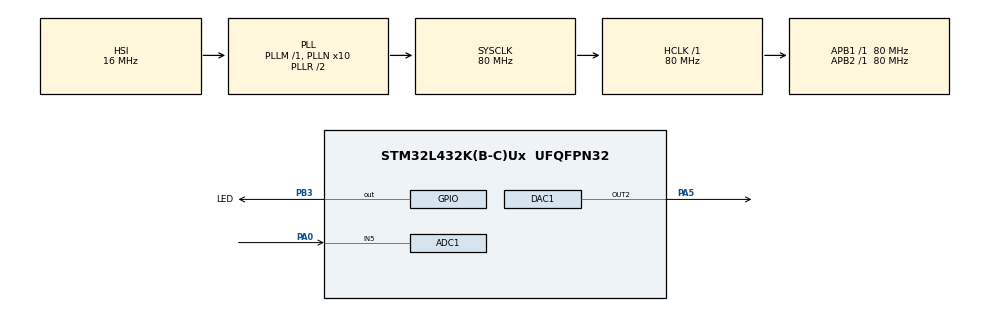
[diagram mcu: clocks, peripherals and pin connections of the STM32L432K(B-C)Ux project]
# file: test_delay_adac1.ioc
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Mcu.Family=STM32L4
RCC.MSI_VALUE=48000000
RCC.PLLSourceVirtual=RCC_PLLSOURCE_HSI
Dma.ADC1.0.Instance=DMA1_Channel1
RCC.CortexFreq_Value=80000000
DAC1.DAC_Channel-DAC_OUT2=DAC_CHANNEL_2
ADC1.Rank-0\#ChannelRegularConversion=1
SH.COMP_DAC12_group.0=DAC1_OUT2,DAC_OUT2
ADC1.OffsetNumber-0\#ChannelRegularConversion=ADC_OFFSET_NONE
PB3\ (JTDO-TRACESWO).GPIO_Label=LED
RCC.SYSCLKSource=RCC_SYSCLKSOURCE_PLLCLK
ProjectManager.StackSize=0x400
PB3\ (JTDO-TRACESWO).Signal=GPIO_Output
RCC.HSI16_VALUE=16000000
Dma.ADC1.0.PeriphDataAlignment=DMA_PDATAALIGN_HALFWORD
ProjectManager.TargetToolchain=STM32CubeIDE
Dma.ADC1.0.Mode=DMA_CIRCULAR
RCC.HCLKFreq_Value=80000000
Dma.ADC1.0.Priority=DMA_PRIORITY_LOW
RCC.APB2TimFreq_Value=80000000
Dma.ADC1.0.Direction=DMA_PERIPH_TO_MEMORY
RCC.USBFreq_Value=80000000
Dma.ADC1.0.MemDataAlignment=DMA_MDATAALIGN_HALFWORD
RCC.AHBFreq_Value=80000000
ADC1.Channel-0\#ChannelRegularConversion=ADC_CHANNEL_5
PA5.Signal=COMP_DAC12_group
RCC.HSE_VALUE=8000000
board=NUCLEO-L432KC
RCC.VCOOutputFreq_Value=160000000
RCC.PLLMUL=RCC_PLLMUL_4
RCC.APB2Freq_Value=80000000
Dma.ADC1.0.PeriphInc=DMA_PINC_DISABLE
RCC.ADCFreq_Value=80000000
Mcu.Name=STM32L432K(B-C)Ux
ADC1.SamplingTime-0\#ChannelRegularConversion=ADC_SAMPLETIME_92CYCLES_5
PA0.Signal=ADCx_IN5
RCC.SYSCLKFreq_VALUE=80000000
Mcu.Package=UFQFPN32
ADC1.master=1
Dma.ADC1.0.MemInc=DMA_MINC_ENABLE
ProjectManager.HeapSize=0x200
RCC.HSI_VALUE=16000000
SH.ADCx_IN5.0=ADC1_IN5,IN5-Single-Ended
NVIC.PriorityGroup=NVIC_PRIORITYGROUP_4
ADC1.NbrOfConversionFlag=1
RCC.PLLN=10
RCC.APB1TimFreq_Value=80000000
NVIC.DMA1_Channel1_IRQn=true\:0\:0\:false\:false\:true\:false\:true
Dma.Request0=ADC1
RCC.APB1Freq_Value=80000000
ADC1.ClockPrescaler=ADC_CLOCK_ASYNC_DIV1
RCC.MSIClockRange=RCC_MSIRANGE_11
RCC.HSI48_VALUE=48000000
RCC.PLLSAI1N=10

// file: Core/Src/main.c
/* USER CODE BEGIN Header */
/**
  ******************************************************************************
  * @file           : main.c
  * @brief          : Main program body
  ******************************************************************************
  * @attention
  *
  * <h2><center>&copy; Copyright (c) 2021 STMicroelectronics.
  * All rights reserved.</center></h2>
  *
  * This software component is licensed by ST under BSD 3-Clause license,
  * the "License"; You may not use this file except in compliance with the
  * License. You may obtain a copy of the License at:
  *                        opensource.org/licenses/BSD-3-Clause
  *
  ******************************************************************************
  */
/* USER CODE END Header */
#include "main.h"

ADC_HandleTypeDef hadc1;
DMA_HandleTypeDef hdma_adc1;

DAC_HandleTypeDef hdac1;

void SystemClock_Config(void);
static void MX_GPIO_Init(void);
static void MX_DMA_Init(void);
static void MX_ADC1_Init(void);
static void MX_DAC1_Init(void);

int main(void)
{
  /* USER CODE BEGIN 1 */
  uint16_t val_adac;

  uint16_t delay = 25000;//32000  max(500ms)
  uint16_t input = 8;//10 - max(full input)
  uint16_t output = 7;//10 - max(full output)
  uint16_t feedback = 40;//100% - max(full feedback)
  uint16_t threshold = 100;

  uint16_t val_delay[delay];

  uint16_t i=1;
  /* USER CODE END 1 */

  /* MCU Configuration--------------------------------------------------------*/

  /* Reset of all peripherals, Initializes the Flash interface and the Systick. */
  HAL_Init();

  /* Configure the system clock */
  SystemClock_Config();

  /* Initialize all configured peripherals */
  MX_GPIO_Init();
  MX_DMA_Init();
  MX_ADC1_Init();
  MX_DAC1_Init();
  /* USER CODE BEGIN 2 */
  HAL_ADCEx_Calibration_Start(&hadc1, ADC_SINGLE_ENDED);

  HAL_ADC_Start_DMA(&hadc1, (uint32_t*)&val_adac, 1);

  HAL_DAC_Start(&hdac1, DAC1_CHANNEL_2);

  HAL_GPIO_WritePin(LED_GPIO_Port, LED_Pin, GPIO_PIN_SET);
  HAL_Delay(100);

  for(int i = 0; i < (delay - 1); i++) val_delay[i] = 0;
  /* USER CODE END 2 */

  /* Infinite loop */
  /* USER CODE BEGIN WHILE */
  while (1)
  {
	  HAL_ADC_Start(&hadc1);

	  if (i == 0){
		  if ((val_adac/10*input + val_delay[delay-1])/100*feedback > threshold) val_delay[delay-1] = (val_adac/10*input + val_delay[delay-1])/100*feedback - threshold;
		  else val_delay[delay-1] = 0;
	  }
  	  else{
  		  if ((val_adac/10*input + val_delay[i-1])/100*feedback > threshold) val_delay[i-1] = (val_adac/10*input + val_delay[i-1])/100*feedback - threshold;
  		  else val_delay[i-1] = 0;
  	  }

	  HAL_DAC_SetValue(&hdac1, DAC1_CHANNEL_2, DAC_ALIGN_12B_R, (val_adac + val_delay[i]/10*output));

	  if (i < (delay - 1)) i++;
	  else{
		  i = 0;
		  HAL_GPIO_TogglePin(LED_GPIO_Port, LED_Pin);
	  }
    /* USER CODE END WHILE */

  }
}

void SystemClock_Config(void)
{
  RCC_OscInitTypeDef RCC_OscInitStruct = {0};
  RCC_ClkInitTypeDef RCC_ClkInitStruct = {0};
  RCC_PeriphCLKInitTypeDef PeriphClkInit = {0};

  /** Initializes the RCC Oscillators according to the specified parameters
  * in the RCC_OscInitTypeDef structure.
  */
  RCC_OscInitStruct.OscillatorType = RCC_OSCILLATORTYPE_HSI;
  RCC_OscInitStruct.HSIState = RCC_HSI_ON;
  RCC_OscInitStruct.HSICalibrationValue = RCC_HSICALIBRATION_DEFAULT;
  RCC_OscInitStruct.PLL.PLLState = RCC_PLL_ON;
  RCC_OscInitStruct.PLL.PLLSource = RCC_PLLSOURCE_HSI;
  RCC_OscInitStruct.PLL.PLLM = 1;
  RCC_OscInitStruct.PLL.PLLN = 10;
  RCC_OscInitStruct.PLL.PLLP = RCC_PLLP_DIV7;
  RCC_OscInitStruct.PLL.PLLQ = RCC_PLLQ_DIV2;
  RCC_OscInitStruct.PLL.PLLR = RCC_PLLR_DIV2;
  if (HAL_RCC_OscConfig(&RCC_OscInitStruct) != HAL_OK)
  {
    Error_Handler();
  }
  /** Initializes the CPU, AHB and APB buses clocks
  */
  RCC_ClkInitStruct.ClockType = RCC_CLOCKTYPE_HCLK|RCC_CLOCKTYPE_SYSCLK
                              |RCC_CLOCKTYPE_PCLK1|RCC_CLOCKTYPE_PCLK2;
  RCC_ClkInitStruct.SYSCLKSource = RCC_SYSCLKSOURCE_PLLCLK;
  RCC_ClkInitStruct.AHBCLKDivider = RCC_SYSCLK_DIV1;
  RCC_ClkInitStruct.APB1CLKDivider = RCC_HCLK_DIV1;
  RCC_ClkInitStruct.APB2CLKDivider = RCC_HCLK_DIV1;

  if (HAL_RCC_ClockConfig(&RCC_ClkInitStruct, FLASH_LATENCY_4) != HAL_OK)
  {
    Error_Handler();
  }
  PeriphClkInit.PeriphClockSelection = RCC_PERIPHCLK_ADC;
  PeriphClkInit.AdcClockSelection = RCC_ADCCLKSOURCE_PLLSAI1;
  PeriphClkInit.PLLSAI1.PLLSAI1Source = RCC_PLLSOURCE_HSI;
  PeriphClkInit.PLLSAI1.PLLSAI1M = 1;
  PeriphClkInit.PLLSAI1.PLLSAI1N = 10;
  PeriphClkInit.PLLSAI1.PLLSAI1P = RCC_PLLP_DIV7;
  PeriphClkInit.PLLSAI1.PLLSAI1Q = RCC_PLLQ_DIV2;
  PeriphClkInit.PLLSAI1.PLLSAI1R = RCC_PLLR_DIV2;
  PeriphClkInit.PLLSAI1.PLLSAI1ClockOut = RCC_PLLSAI1_ADC1CLK;
  if (HAL_RCCEx_PeriphCLKConfig(&PeriphClkInit) != HAL_OK)
  {
    Error_Handler();
  }
  /** Configure the main internal regulator output voltage
  */
  if (HAL_PWREx_ControlVoltageScaling(PWR_REGULATOR_VOLTAGE_SCALE1) != HAL_OK)
  {
    Error_Handler();
  }
}

static void MX_ADC1_Init(void)
{

  ADC_ChannelConfTypeDef sConfig = {0};

  /** Common config
  */
  hadc1.Instance = ADC1;
  hadc1.Init.ClockPrescaler = ADC_CLOCK_ASYNC_DIV1;
  hadc1.Init.Resolution = ADC_RESOLUTION_12B;
  hadc1.Init.DataAlign = ADC_DATAALIGN_RIGHT;
  hadc1.Init.ScanConvMode = ADC_SCAN_DISABLE;
  hadc1.Init.EOCSelection = ADC_EOC_SINGLE_CONV;
  hadc1.Init.LowPowerAutoWait = DISABLE;
  hadc1.Init.ContinuousConvMode = DISABLE;
  hadc1.Init.NbrOfConversion = 1;
  hadc1.Init.DiscontinuousConvMode = DISABLE;
  hadc1.Init.ExternalTrigConv = ADC_SOFTWARE_START;
  hadc1.Init.ExternalTrigConvEdge = ADC_EXTERNALTRIGCONVEDGE_NONE;
  hadc1.Init.DMAContinuousRequests = DISABLE;
  hadc1.Init.Overrun = ADC_OVR_DATA_PRESERVED;
  hadc1.Init.OversamplingMode = DISABLE;
  if (HAL_ADC_Init(&hadc1) != HAL_OK)
  {
    Error_Handler();
  }
  /** Configure Regular Channel
  */
  sConfig.Channel = ADC_CHANNEL_5;
  sConfig.Rank = ADC_REGULAR_RANK_1;
  sConfig.SamplingTime = ADC_SAMPLETIME_92CYCLES_5;
  sConfig.SingleDiff = ADC_SINGLE_ENDED;
  sConfig.OffsetNumber = ADC_OFFSET_NONE;
  sConfig.Offset = 0;
  if (HAL_ADC_ConfigChannel(&hadc1, &sConfig) != HAL_OK)
  {
    Error_Handler();
  }

}

static void MX_DAC1_Init(void)
{

  DAC_ChannelConfTypeDef sConfig = {0};

  /** DAC Initialization
  */
  hdac1.Instance = DAC1;
  if (HAL_DAC_Init(&hdac1) != HAL_OK)
  {
    Error_Handler();
  }
  /** DAC channel OUT2 config
  */
  sConfig.DAC_SampleAndHold = DAC_SAMPLEANDHOLD_DISABLE;
  sConfig.DAC_Trigger = DAC_TRIGGER_NONE;
  sConfig.DAC_OutputBuffer = DAC_OUTPUTBUFFER_ENABLE;
  sConfig.DAC_ConnectOnChipPeripheral = DAC_CHIPCONNECT_DISABLE;
  sConfig.DAC_UserTrimming = DAC_TRIMMING_FACTORY;
  if (HAL_DAC_ConfigChannel(&hdac1, &sConfig, DAC_CHANNEL_2) != HAL_OK)
  {
    Error_Handler();
  }

}

static void MX_DMA_Init(void)
{

  /* DMA controller clock enable */
  __HAL_RCC_DMA1_CLK_ENABLE();

  /* DMA interrupt init */
  /* DMA1_Channel1_IRQn interrupt configuration */
  HAL_NVIC_SetPriority(DMA1_Channel1_IRQn, 0, 0);
  HAL_NVIC_EnableIRQ(DMA1_Channel1_IRQn);

}

static void MX_GPIO_Init(void)
{
  GPIO_InitTypeDef GPIO_InitStruct = {0};

  /* GPIO Ports Clock Enable */
  __HAL_RCC_GPIOA_CLK_ENABLE();
  __HAL_RCC_GPIOB_CLK_ENABLE();

  /*Configure GPIO pin Output Level */
  HAL_GPIO_WritePin(LED_GPIO_Port, LED_Pin, GPIO_PIN_RESET);

  /*Configure GPIO pin : LED_Pin */
  GPIO_InitStruct.Pin = LED_Pin;
  GPIO_InitStruct.Mode = GPIO_MODE_OUTPUT_PP;
  GPIO_InitStruct.Pull = GPIO_NOPULL;
  GPIO_InitStruct.Speed = GPIO_SPEED_FREQ_LOW;
  HAL_GPIO_Init(LED_GPIO_Port, &GPIO_InitStruct);

}

void Error_Handler(void)
{
  __disable_irq();
  while (1)
  {
  }
}

/************************ (C) COPYRIGHT STMicroelectronics *****END OF FILE****/
